# MSPM0G150X register map
Vendor: Texas Instruments; File version: This preliminary header file does not have a version number - build date: 2023-02-21 16:25:48
CPU: CM0 r0p1, little endian, MPU, no FPU, 3 interrupt priority bits
Registers are 32-bit, read-write, reset 0x0 unless marked. A register's access mark holds for its fields unless they carry their own. Offsets are from the block's base; [hi:lo] are bit positions; {n}, {i} and the like mark numbered series.

## DMA — PERIPHERALREGION
Base 0x4042A000
0x400 FSUB_0 — Subscriber Port 0
  [3:0] FSUB_0_CHANID — 0 = disconnected. 1-255 = connected to channelID = CHANID.
    0=FSUB_0_CHANID_UNCONNECTED (UNCONNECTED)
0x404 FSUB_1 — Subscriber Port 1
  [3:0] FSUB_1_CHANID — 0 = disconnected. 1-255 = connected to channelID = CHANID.
    0=FSUB_1_CHANID_UNCONNECTED (UNCONNECTED)
0x444 FPUB_1 — Publisher Port 0
  [3:0] FPUB_1_CHANID — 0 = disconnected. 1-255 = connected to channelID = CHANID.
    0=FPUB_1_CHANID_UNCONNECTED (UNCONNECTED)
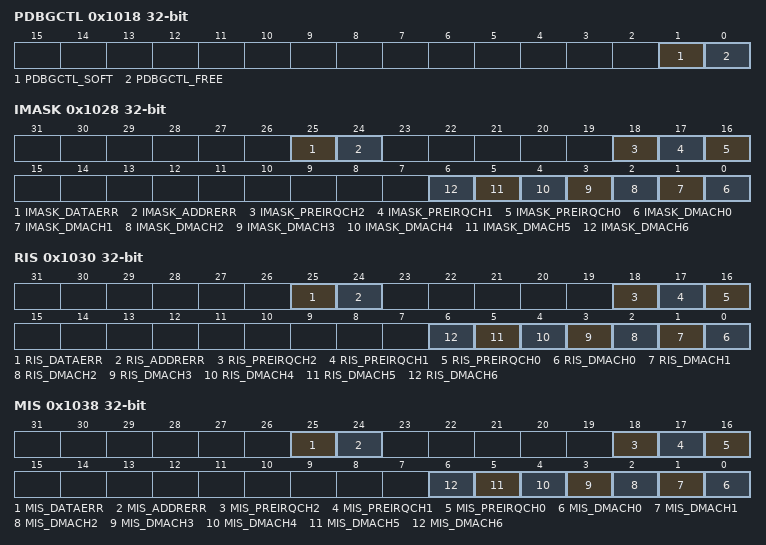
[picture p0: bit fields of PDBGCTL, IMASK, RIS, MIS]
0x1018 PDBGCTL — Peripheral Debug Control
  [1] PDBGCTL_SOFT — Soft halt boundary control. This function is only available, if [FREE] is set to 'STOP'
    0=PDBGCTL_SOFT_IMMEDIATE (IMMEDIATE); 1=PDBGCTL_SOFT_DELAYED (DELAYED)
  [0] PDBGCTL_FREE — Free run control
    0=PDBGCTL_FREE_STOP (STOP); 1=PDBGCTL_FREE_RUN (RUN)
0x1020 IIDX ro — Interrupt index
  [7:0] IIDX_STAT — Interrupt index status
    0=IIDX_STAT_NO_INTR (NO_INTR); {v}=IIDX_STAT_DMACH{v-1} (DMACH{v-1}) (v=1..16); {v}=IIDX_STAT_PREIRQCH{v-17} (PREIRQCH{v-17}) (v=17..24); 25=IIDX_STAT_ADDRERR (ADDRERR); 26=IIDX_STAT_DATAERR (DATAERR)
0x1028 IMASK — Interrupt mask
  [25] IMASK_DATAERR — DMA data error, SRC data might be corrupted (PAR or ECC error).
    0=IMASK_DATAERR_CLR (CLR); 1=IMASK_DATAERR_SET (SET)
  [24] IMASK_ADDRERR — DMA address error, SRC address not reachable.
    0=IMASK_ADDRERR_CLR (CLR); 1=IMASK_ADDRERR_SET (SET)
  [18] IMASK_PREIRQCH2 — Pre-IRQ for Channel 2. Size counter reached Pre-IRQ threshold.
    0=IMASK_PREIRQCH2_CLR (CLR); 1=IMASK_PREIRQCH2_SET (SET)
  [17] IMASK_PREIRQCH1 — Pre-IRQ for Channel 1. Size counter reached Pre-IRQ threshold.
    0=IMASK_PREIRQCH1_CLR (CLR); 1=IMASK_PREIRQCH1_SET (SET)
  [16] IMASK_PREIRQCH0 — Pre-IRQ for Channel 0. Size counter reached Pre-IRQ threshold.
    0=IMASK_PREIRQCH0_CLR (CLR); 1=IMASK_PREIRQCH0_SET (SET)
  [n] IMASK_DMACH{n} (n=0..6) — DMA Channel {n} interrupt signal. Size counter reached zero (DMASZ=0).
    0=IMASK_DMACH{n}_CLR (CLR); 1=IMASK_DMACH{n}_SET (SET)
0x1030 RIS ro — Raw interrupt status
  [25] RIS_DATAERR — DMA data error, SRC data might be corrupted (PAR or ECC error).
    0=RIS_DATAERR_CLR (CLR); 1=RIS_DATAERR_SET (SET)
  [24] RIS_ADDRERR — DMA address error, SRC address not reachable.
    0=RIS_ADDRERR_CLR (CLR); 1=RIS_ADDRERR_SET (SET)
  [18] RIS_PREIRQCH2 — Pre-IRQ for Channel 2. Size counter reached Pre-IRQ threshold.
    0=RIS_PREIRQCH2_CLR (CLR); 1=RIS_PREIRQCH2_SET (SET)
  [17] RIS_PREIRQCH1 — Pre-IRQ for Channel 1. Size counter reached Pre-IRQ threshold.
    0=RIS_PREIRQCH1_CLR (CLR); 1=RIS_PREIRQCH1_SET (SET)
  [16] RIS_PREIRQCH0 — Pre-IRQ for Channel 0. Size counter reached Pre-IRQ threshold.
    0=RIS_PREIRQCH0_CLR (CLR); 1=RIS_PREIRQCH0_SET (SET)
  [n] RIS_DMACH{n} (n=0..6) — DMA Channel {n} interrupt signals that size counter reached zero (DMASZ=0).
    0=RIS_DMACH{n}_CLR (CLR); 1=RIS_DMACH{n}_SET (SET)
0x1038 MIS ro — Masked interrupt status
  [25] MIS_DATAERR — DMA data error, SRC data might be corrupted (PAR or ECC error).
    0=MIS_DATAERR_CLR (CLR); 1=MIS_DATAERR_SET (SET)
  [24] MIS_ADDRERR — DMA address error, SRC address not reachable.
    0=MIS_ADDRERR_CLR (CLR); 1=MIS_ADDRERR_SET (SET)
  [18] MIS_PREIRQCH2 — Pre-IRQ for Channel 2. Size counter reached Pre-IRQ threshold.
    0=MIS_PREIRQCH2_CLR (CLR); 1=MIS_PREIRQCH2_SET (SET)
  [17] MIS_PREIRQCH1 — Pre-IRQ for Channel 1. Size counter reached Pre-IRQ threshold.
    0=MIS_PREIRQCH1_CLR (CLR); 1=MIS_PREIRQCH1_SET (SET)
  [16] MIS_PREIRQCH0 — Pre-IRQ for Channel 0. Size counter reached Pre-IRQ threshold.
    0=MIS_PREIRQCH0_CLR (CLR); 1=MIS_PREIRQCH0_SET (SET)
  [n] MIS_DMACH{n} (n=0..6) — DMA Channel {n} interrupt signals that size counter reached zero (DMASZ=0).
    0=MIS_DMACH{n}_CLR (CLR); 1=MIS_DMACH{n}_SET (SET)
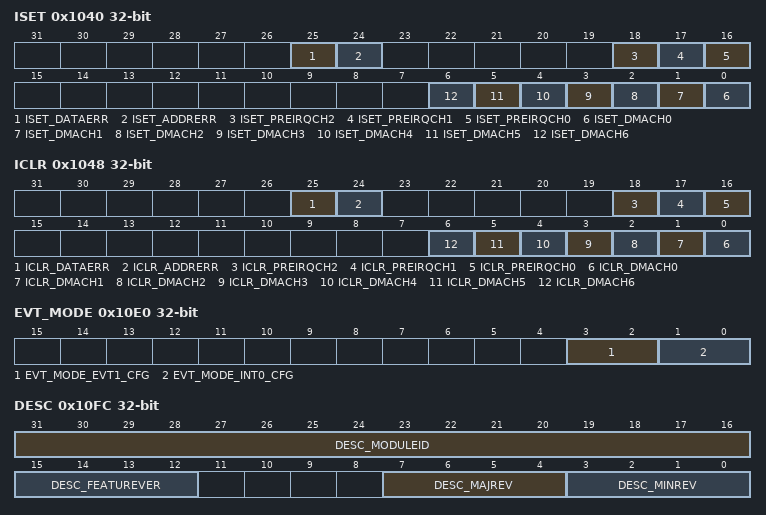
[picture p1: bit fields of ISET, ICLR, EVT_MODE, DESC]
0x1040 ISET wo — Interrupt set
  [25] ISET_DATAERR — DMA data error, SRC data might be corrupted (PAR or ECC error).
    0=ISET_DATAERR_CLR (CLR); 1=ISET_DATAERR_SET (SET)
  [24] ISET_ADDRERR — DMA address error, SRC address not reachable.
    0=ISET_ADDRERR_CLR (CLR); 1=ISET_ADDRERR_SET (SET)
  [18] ISET_PREIRQCH2 — Pre-IRQ for Channel 2. Size counter reached Pre-IRQ threshold.
    0=ISET_PREIRQCH2_CLR (CLR); 1=ISET_PREIRQCH2_SET (SET)
  [17] ISET_PREIRQCH1 — Pre-IRQ for Channel 1. Size counter reached Pre-IRQ threshold.
    0=ISET_PREIRQCH1_CLR (CLR); 1=ISET_PREIRQCH1_SET (SET)
  [16] ISET_PREIRQCH0 — Pre-IRQ for Channel 0. Size counter reached Pre-IRQ threshold.
    0=ISET_PREIRQCH0_CLR (CLR); 1=ISET_PREIRQCH0_SET (SET)
  [n] ISET_DMACH{n} (n=0..6) — DMA Channel {n} interrupt signals that size counter reached zero (DMASZ=0).
    0=ISET_DMACH{n}_NO_EFFECT (NO_EFFECT); 1=ISET_DMACH{n}_SET (SET)
0x1048 ICLR wo — Interrupt clear
  [25] ICLR_DATAERR — DMA data error, SRC data might be corrupted (PAR or ECC error).
    0=ICLR_DATAERR_CLR (CLR); 1=ICLR_DATAERR_SET (SET)
  [24] ICLR_ADDRERR — DMA address error, SRC address not reachable.
    0=ICLR_ADDRERR_CLR (CLR); 1=ICLR_ADDRERR_SET (SET)
  [18] ICLR_PREIRQCH2 — Pre-IRQ for Channel 2. Size counter reached Pre-IRQ threshold.
    0=ICLR_PREIRQCH2_CLR (CLR); 1=ICLR_PREIRQCH2_SET (SET)
  [17] ICLR_PREIRQCH1 — Pre-IRQ for Channel 1. Size counter reached Pre-IRQ threshold.
    0=ICLR_PREIRQCH1_CLR (CLR); 1=ICLR_PREIRQCH1_SET (SET)
  [16] ICLR_PREIRQCH0 — Pre-IRQ for Channel 0. Size counter reached Pre-IRQ threshold.
    0=ICLR_PREIRQCH0_CLR (CLR); 1=ICLR_PREIRQCH0_SET (SET)
  [n] ICLR_DMACH{n} (n=0..6) — DMA Channel {n} interrupt signals that size counter reached zero (DMASZ=0).
    0=ICLR_DMACH{n}_NO_EFFECT (NO_EFFECT); 1=ICLR_DMACH{n}_CLR (CLR)
0x10E0 EVT_MODE — Event Mode
  [3:2] EVT_MODE_EVT1_CFG ro — Event line mode select for event corresponding to generic event INT_EVENT[1]
    0=EVT_MODE_EVT1_CFG_DISABLE (DISABLE); 1=EVT_MODE_EVT1_CFG_SOFTWARE (SOFTWARE); 2=EVT_MODE_EVT1_CFG_HARDWARE (HARDWARE)
  [1:0] EVT_MODE_INT0_CFG ro — Event line mode select for event corresponding to interrupt event INT_EVENT[0]
    0=EVT_MODE_INT0_CFG_DISABLE (DISABLE); 1=EVT_MODE_INT0_CFG_SOFTWARE (SOFTWARE); 2=EVT_MODE_INT0_CFG_HARDWARE (HARDWARE)
0x10FC DESC ro — Module Description
  [31:16] DESC_MODULEID — Module identification contains a unique peripheral identification number. The assignments are maintained in a central database for all of the platform modules to ensure uniqueness.
  [15:12] DESC_FEATUREVER — Feature Set for the DMA: number of DMA channel minus one (e.g. 0->1ch, 2->3ch, 15->16ch).
  [7:4] DESC_MAJREV — Major rev of the IP
  [3:0] DESC_MINREV — Minor rev of the IP
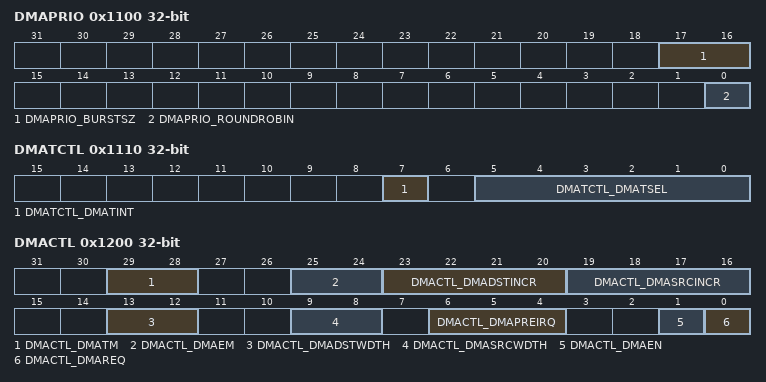
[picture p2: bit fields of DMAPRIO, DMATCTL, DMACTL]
0x1100 DMAPRIO — DMA Channel Priority Control
  [17:16] DMAPRIO_BURSTSZ — Define the burst size of a block transfer, before the priority is re-evaluated
    0=DMAPRIO_BURSTSZ_INFINITI (INFINITI); 1=DMAPRIO_BURSTSZ_BURST_8 (BURST_8); 2=DMAPRIO_BURSTSZ_BUSRT_16 (BUSRT_16); 3=DMAPRIO_BURSTSZ_BURST_32 (BURST_32)
  [0] DMAPRIO_ROUNDROBIN — Round robin. This bit enables the round-robin DMA channel priorities.
    0=DMAPRIO_ROUNDROBIN_DISABLE (DISABLE); 1=DMAPRIO_ROUNDROBIN_ENABLE (ENABLE)
0x1110 DMATCTL — DMA Trigger Select
  [7] DMATCTL_DMATINT — DMA Trigger by Internal Channel
    0=DMATCTL_DMATINT_EXTERNAL (EXTERNAL); 1=DMATCTL_DMATINT_INTERNAL (INTERNAL)
  [5:0] DMATCTL_DMATSEL — DMA Trigger Select Note: Reference the datasheet of the device to see the specific trigger mapping.
    0=DMATCTL_DMATSEL_DMAREQ (DMAREQ)
0x1200 DMACTL — DMA Channel Control
  [29:28] DMACTL_DMATM — DMA transfer mode register Note: The repeat-single (2h) and repeat-block (3h) transfer are only available in a FULL-channel configuration. Please consult the datasheet of the specific device to map which channel number has FULL or BASIC capability. In a BASIC channel configuration only the values for single (0h) and block (1h) transfer can be set.
    0=DMACTL_DMATM_SINGLE (SINGLE); 1=DMACTL_DMATM_BLOCK (BLOCK); 2=DMACTL_DMATM_RPTSNGL (RPTSNGL); 3=DMACTL_DMATM_RPTBLCK (RPTBLCK)
  [25:24] DMACTL_DMAEM — DMA extended mode Note: The extended transfer modes are only available in a FULL-channel configuration. Please consult the datasheet of the specific device to map which channel number has FULL or BASIC capability. In a BASIC channel configuration this register is a read-only register and reads 0x0.
    0=DMACTL_DMAEM_NORMAL (NORMAL); 2=DMACTL_DMAEM_FILLMODE (FILLMODE); 3=DMACTL_DMAEM_TABLEMODE (TABLEMODE)
  [23:20] DMACTL_DMADSTINCR — DMA destination increment. This bit selects automatic incrementing or decrementing of the destination address DMADA for each transfer. The amount of change to the DMADA is based on the definitin in the DMADSTWDTH. For example an increment of 1 (+1) on a WORD transfer will increment the DMADA by 4.
    0=DMACTL_DMADSTINCR_UNCHANGED (UNCHANGED); 2=DMACTL_DMADSTINCR_DECREMENT (DECREMENT); 3=DMACTL_DMADSTINCR_INCREMENT (INCREMENT); {v}=DMACTL_DMADSTINCR_STRIDE_{v-6} (STRIDE_{v-6}) (v=8..15)
  [19:16] DMACTL_DMASRCINCR — DMA source increment. This bit selects automatic incrementing or decrementing of the source address DMASA for each transfer. The amount of change to the DMASA is based on the definitin in the DMASRCWDTH. For example an increment of 1 (+1) on a WORD transfer will increment the DMASA by 4.
    0=DMACTL_DMASRCINCR_UNCHANGED (UNCHANGED); 2=DMACTL_DMASRCINCR_DECREMENT (DECREMENT); 3=DMACTL_DMASRCINCR_INCREMENT (INCREMENT); {v}=DMACTL_DMASRCINCR_STRIDE_{v-6} (STRIDE_{v-6}) (v=8..15)
  [13:12] DMACTL_DMADSTWDTH — DMA destination width. This bit selects the destination as a byte, half word, word or long word.
    0=DMACTL_DMADSTWDTH_BYTE (BYTE); 1=DMACTL_DMADSTWDTH_HALF (HALF); 2=DMACTL_DMADSTWDTH_WORD (WORD); 3=DMACTL_DMADSTWDTH_LONG (LONG)
  [9:8] DMACTL_DMASRCWDTH — DMA source width. This bit selects the source data width as a byte, half word, word or long word.
    0=DMACTL_DMASRCWDTH_BYTE (BYTE); 1=DMACTL_DMASRCWDTH_HALF (HALF); 2=DMACTL_DMASRCWDTH_WORD (WORD); 3=DMACTL_DMASRCWDTH_LONG (LONG)
  [6:4] DMACTL_DMAPREIRQ — Enable an early IRQ event. This can help software to react quicker to and DMA done event or allows some additional configuration before the channel is complete. Note: This register is only available in a FULL-channel configuration. Please consult the datasheet of the specific device to map which channel number has FULL or BASIC capability. In a BASIC configuration this register is a read only value and always reads as 0x0.
    0=DMACTL_DMAPREIRQ_PREIRQ_DISABLE (PREIRQ_DISABLE); 1=DMACTL_DMAPREIRQ_PREIRQ_1 (PREIRQ_1); 2=DMACTL_DMAPREIRQ_PREIRQ_2 (PREIRQ_2); 3=DMACTL_DMAPREIRQ_PREIRQ_4 (PREIRQ_4); 4=DMACTL_DMAPREIRQ_PREIRQ_8 (PREIRQ_8); 5=DMACTL_DMAPREIRQ_PREIRQ_32 (PREIRQ_32); 6=DMACTL_DMAPREIRQ_PREIRQ_64 (PREIRQ_64); 7=DMACTL_DMAPREIRQ_PREIRQ_HALF (PREIRQ_HALF)
  [1] DMACTL_DMAEN — DMA enable
    0=DMACTL_DMAEN_DISABLE (DISABLE); 1=DMACTL_DMAEN_ENABLE (ENABLE)
  [0] DMACTL_DMAREQ — DMA request. Software-controlled DMA start. DMAREQ is reset automatically.
    0=DMACTL_DMAREQ_IDLE (IDLE); 1=DMACTL_DMAREQ_REQUEST (REQUEST)
0x1204 DMASA — DMA Channel Source Address
  [31:0] DMASA_ADDR
0x1208 DMADA — DMA Channel Destination Address
  [31:0] DMADA_ADDR
0x120C DMASZ — DMA Channel Size
  [15:0] DMASZ_SIZE — DMA Channel Size in number of transfers
